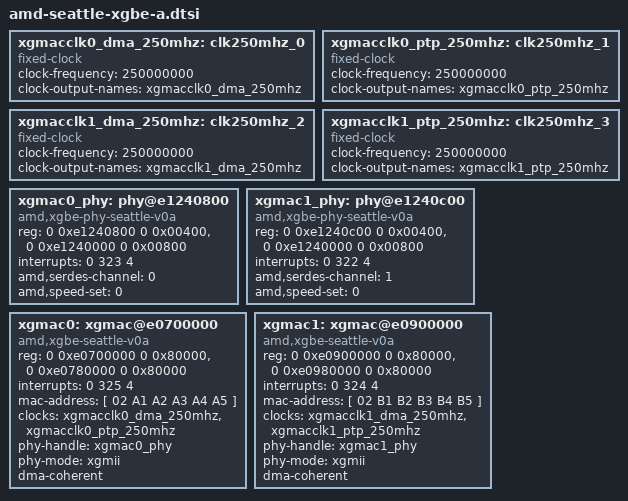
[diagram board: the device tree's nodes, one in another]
/*
 * DTS file for AMD Seattle XGBE (RevA)
 *
 * Copyright (C) 2014 Advanced Micro Devices, Inc.
 */

        xgmacclk0_dma_250mhz: clk250mhz_0 {
                compatible = "fixed-clock";
                #clock-cells = <0>;
                clock-frequency = <250000000>;
                clock-output-names = "xgmacclk0_dma_250mhz";
        };

        xgmacclk0_ptp_250mhz: clk250mhz_1 {
                compatible = "fixed-clock";
                #clock-cells = <0>;
                clock-frequency = <250000000>;
                clock-output-names = "xgmacclk0_ptp_250mhz";
        };

        xgmacclk1_dma_250mhz: clk250mhz_2 {
                compatible = "fixed-clock";
                #clock-cells = <0>;
                clock-frequency = <250000000>;
                clock-output-names = "xgmacclk1_dma_250mhz";
        };

        xgmacclk1_ptp_250mhz: clk250mhz_3 {
                compatible = "fixed-clock";
                #clock-cells = <0>;
                clock-frequency = <250000000>;
                clock-output-names = "xgmacclk1_ptp_250mhz";
        };
	xgmac0_phy: phy@e1240800 {
		compatible = "amd,xgbe-phy-seattle-v0a";
		reg = <0 0xe1240800 0 0x00400>, /* SERDES RX/TX0 */
		      <0 0xe1240000 0 0x00800>; /* SERDES CMUs */
		interrupts = <0 323 4>;
		amd,serdes-channel = <0>;
		amd,speed-set = <0>;
	};

	xgmac1_phy: phy@e1240c00 {
		compatible = "amd,xgbe-phy-seattle-v0a";
		reg = <0 0xe1240c00 0 0x00400>, /* SERDES RX/TX1 */
		      <0 0xe1240000 0 0x00800>; /* SERDES CMUs */
		interrupts = <0 322 4>;
		amd,serdes-channel = <1>;
		amd,speed-set = <0>;
	};

	xgmac0: xgmac@e0700000 {
		compatible = "amd,xgbe-seattle-v0a";
		reg = <0 0xe0700000 0 0x80000>,
		      <0 0xe0780000 0 0x80000>;
		interrupts = <0 325 4>;
		mac-address = [ 02 A1 A2 A3 A4 A5 ];
		clocks = <&xgmacclk0_dma_250mhz>, <&xgmacclk0_ptp_250mhz>;
		clock-names = "dma_clk", "ptp_clk";
		phy-handle = <&xgmac0_phy>;
		phy-mode = "xgmii";
		#stream-id-cells = <24>;
		dma-coherent;
	};

	xgmac1: xgmac@e0900000 {
		compatible = "amd,xgbe-seattle-v0a";
		reg = <0 0xe0900000 0 0x80000>,
		      <0 0xe0980000 0 0x80000>;
		interrupts = <0 324 4>;
		mac-address = [ 02 B1 B2 B3 B4 B5 ];
		clocks = <&xgmacclk1_dma_250mhz>, <&xgmacclk1_ptp_250mhz>;
		clock-names = "dma_clk", "ptp_clk";
		phy-handle = <&xgmac1_phy>;
		phy-mode = "xgmii";
		#stream-id-cells = <24>;
		dma-coherent;
	};
